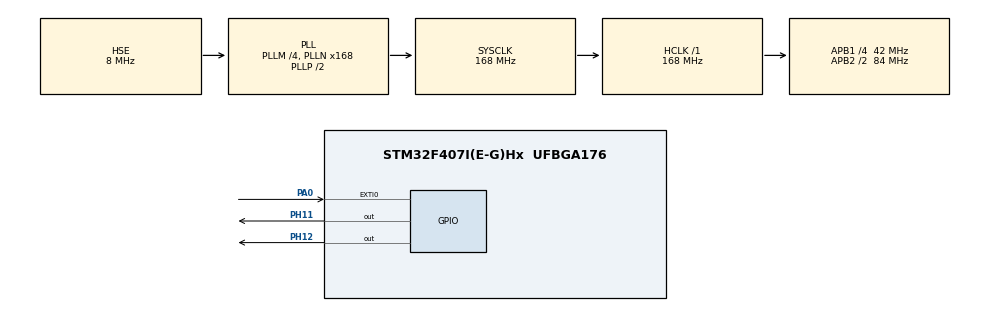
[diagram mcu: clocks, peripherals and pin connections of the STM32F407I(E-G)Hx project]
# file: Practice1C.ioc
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Mcu.Family=STM32F4
Mcu.Name=STM32F407I(E-G)Hx
Mcu.Package=UFBGA176
NVIC.EXTI0_IRQn=true\:0\:0\:false\:false\:true\:true\:true\:true
NVIC.PriorityGroup=NVIC_PRIORITYGROUP_4
NVIC.TIM3_IRQn=true\:0\:0\:false\:false\:true\:true\:true\:true
PA0-WKUP.GPIO_PuPd=GPIO_PULLDOWN
PA0-WKUP.Signal=GPXTI0
PA13.Mode=Serial_Wire
PA13.Signal=SYS_JTMS-SWDIO
PA14.Mode=Serial_Wire
PA14.Signal=SYS_JTCK-SWCLK
PH0-OSC_IN.Mode=HSE-External-Oscillator
PH0-OSC_IN.Signal=RCC_OSC_IN
PH1-OSC_OUT.Mode=HSE-External-Oscillator
PH1-OSC_OUT.Signal=RCC_OSC_OUT
PH11.PinState=GPIO_PIN_SET
PH11.Signal=GPIO_Output
PH12.PinState=GPIO_PIN_SET
PH12.Signal=GPIO_Output
ProjectManager.HeapSize=0x200
ProjectManager.StackSize=0x400
ProjectManager.TargetToolchain=CMake
RCC.48MHZClocksFreq_Value=84000000
RCC.AHBFreq_Value=168000000
RCC.APB1CLKDivider=RCC_HCLK_DIV4
RCC.APB1Freq_Value=42000000
RCC.APB1TimFreq_Value=84000000
RCC.APB2CLKDivider=RCC_HCLK_DIV2
RCC.APB2Freq_Value=84000000
RCC.APB2TimFreq_Value=168000000
RCC.CortexFreq_Value=168000000
RCC.HCLKFreq_Value=168000000
RCC.HSE_VALUE=8000000
RCC.HSI_VALUE=16000000
RCC.LSE_VALUE=32768
RCC.PLLM=4
RCC.PLLN=168
RCC.PLLSourceVirtual=RCC_PLLSOURCE_HSE
RCC.SYSCLKFreq_VALUE=168000000
RCC.SYSCLKSource=RCC_SYSCLKSOURCE_PLLCLK
RCC.VCOOutputFreq_Value=336000000
TIM3.Period=4999
TIM3.Prescaler=16799
VP_TIM3_VS_ClockSourceINT.Mode=Internal
board=custom

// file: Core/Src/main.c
/* USER CODE BEGIN Header */
/**
  ******************************************************************************
  * @file           : main.c
  * @brief          : Main program body
  ******************************************************************************
  * @attention
  *
  * Copyright (c) 2026 STMicroelectronics.
  * All rights reserved.
  *
  * This software is licensed under terms that can be found in the LICENSE file
  * in the root directory of this software component.
  * If no LICENSE file comes with this software, it is provided AS-IS.
  *
  ******************************************************************************
  */
/* USER CODE END Header */
#include "main.h"

/* USER CODE BEGIN PD */
volatile uint8_t tim3_event = 0;
/* USER CODE END PD */

TIM_HandleTypeDef htim3;

void SystemClock_Config(void);
static void MX_GPIO_Init(void);
static void MX_TIM3_Init(void);

int main(void)
{

  /* MCU Configuration--------------------------------------------------------*/

  /* Reset of all peripherals, Initializes the Flash interface and the Systick. */
  HAL_Init();

  /* Configure the system clock */
  SystemClock_Config();

  /* Initialize all configured peripherals */
  MX_GPIO_Init();
  MX_TIM3_Init();
  /* USER CODE BEGIN 2 */
   HAL_TIM_Base_Start_IT(&htim3);

  /* USER CODE END 2 */

  /* Infinite loop */
  /* USER CODE BEGIN WHILE */
  while (1)
  {

    HAL_GPIO_WritePin(GPIOH, GPIO_PIN_12, GPIO_PIN_RESET);
    HAL_GPIO_WritePin(GPIOH, GPIO_PIN_11, GPIO_PIN_SET);
    //HAL_GPIO_WritePin(GPIOH, GPIO_PIN_11, GPIO_PIN_SET);
    HAL_Delay(100);
     if (tim3_event == 1)
    {
        tim3_event = 0;  // 清除标志位

        // 在这里随便用 HAL_Delay，绝对安全！
        HAL_GPIO_TogglePin(GPIOH, GPIO_PIN_11); // 开灯
        HAL_GPIO_TogglePin(GPIOH, GPIO_PIN_12); // 关灯
        HAL_Delay(1000);                       // 延时 1 秒
    }
    /* USER CODE END WHILE */

  }
}

void SystemClock_Config(void)
{
  RCC_OscInitTypeDef RCC_OscInitStruct = {0};
  RCC_ClkInitTypeDef RCC_ClkInitStruct = {0};

  /** Configure the main internal regulator output voltage
  */
  __HAL_RCC_PWR_CLK_ENABLE();
  __HAL_PWR_VOLTAGESCALING_CONFIG(PWR_REGULATOR_VOLTAGE_SCALE1);

  /** Initializes the RCC Oscillators according to the specified parameters
  * in the RCC_OscInitTypeDef structure.
  */
  RCC_OscInitStruct.OscillatorType = RCC_OSCILLATORTYPE_HSE;
  RCC_OscInitStruct.HSEState = RCC_HSE_ON;
  RCC_OscInitStruct.PLL.PLLState = RCC_PLL_ON;
  RCC_OscInitStruct.PLL.PLLSource = RCC_PLLSOURCE_HSE;
  RCC_OscInitStruct.PLL.PLLM = 4;
  RCC_OscInitStruct.PLL.PLLN = 168;
  RCC_OscInitStruct.PLL.PLLP = RCC_PLLP_DIV2;
  RCC_OscInitStruct.PLL.PLLQ = 4;
  if (HAL_RCC_OscConfig(&RCC_OscInitStruct) != HAL_OK)
  {
    Error_Handler();
  }

  /** Initializes the CPU, AHB and APB buses clocks
  */
  RCC_ClkInitStruct.ClockType = RCC_CLOCKTYPE_HCLK|RCC_CLOCKTYPE_SYSCLK
                              |RCC_CLOCKTYPE_PCLK1|RCC_CLOCKTYPE_PCLK2;
  RCC_ClkInitStruct.SYSCLKSource = RCC_SYSCLKSOURCE_PLLCLK;
  RCC_ClkInitStruct.AHBCLKDivider = RCC_SYSCLK_DIV1;
  RCC_ClkInitStruct.APB1CLKDivider = RCC_HCLK_DIV4;
  RCC_ClkInitStruct.APB2CLKDivider = RCC_HCLK_DIV2;

  if (HAL_RCC_ClockConfig(&RCC_ClkInitStruct, FLASH_LATENCY_5) != HAL_OK)
  {
    Error_Handler();
  }
}

static void MX_TIM3_Init(void)
{

  TIM_ClockConfigTypeDef sClockSourceConfig = {0};
  TIM_MasterConfigTypeDef sMasterConfig = {0};

  htim3.Instance = TIM3;
  htim3.Init.Prescaler = 16799;
  htim3.Init.CounterMode = TIM_COUNTERMODE_UP;
  htim3.Init.Period = 4999;
  htim3.Init.ClockDivision = TIM_CLOCKDIVISION_DIV1;
  htim3.Init.AutoReloadPreload = TIM_AUTORELOAD_PRELOAD_DISABLE;
  if (HAL_TIM_Base_Init(&htim3) != HAL_OK)
  {
    Error_Handler();
  }
  sClockSourceConfig.ClockSource = TIM_CLOCKSOURCE_INTERNAL;
  if (HAL_TIM_ConfigClockSource(&htim3, &sClockSourceConfig) != HAL_OK)
  {
    Error_Handler();
  }
  sMasterConfig.MasterOutputTrigger = TIM_TRGO_RESET;
  sMasterConfig.MasterSlaveMode = TIM_MASTERSLAVEMODE_DISABLE;
  if (HAL_TIMEx_MasterConfigSynchronization(&htim3, &sMasterConfig) != HAL_OK)
  {
    Error_Handler();
  }

}

static void MX_GPIO_Init(void)
{
  GPIO_InitTypeDef GPIO_InitStruct = {0};

  /* GPIO Ports Clock Enable */
  __HAL_RCC_GPIOA_CLK_ENABLE();
  __HAL_RCC_GPIOH_CLK_ENABLE();

  /*Configure GPIO pin Output Level */
  HAL_GPIO_WritePin(GPIOH, GPIO_PIN_12|GPIO_PIN_11, GPIO_PIN_SET);

  /*Configure GPIO pins : PH12 PH11 */
  GPIO_InitStruct.Pin = GPIO_PIN_12|GPIO_PIN_11;
  GPIO_InitStruct.Mode = GPIO_MODE_OUTPUT_PP;
  GPIO_InitStruct.Pull = GPIO_NOPULL;
  GPIO_InitStruct.Speed = GPIO_SPEED_FREQ_LOW;
  HAL_GPIO_Init(GPIOH, &GPIO_InitStruct);

  /*Configure GPIO pin : PA0 */
  GPIO_InitStruct.Pin = GPIO_PIN_0;
  GPIO_InitStruct.Mode = GPIO_MODE_IT_RISING;
  GPIO_InitStruct.Pull = GPIO_PULLDOWN;
  HAL_GPIO_Init(GPIOA, &GPIO_InitStruct);

  /* EXTI interrupt init*/
  HAL_NVIC_SetPriority(EXTI0_IRQn, 0, 0);
  HAL_NVIC_EnableIRQ(EXTI0_IRQn);

}

/* USER CODE BEGIN 4 */
void HAL_TIM_PeriodElapsedCallback(TIM_HandleTypeDef *htim)
{
   tim3_event = 1;
    //TODO
}
/* USER CODE END 4 */

void Error_Handler(void)
{
  /* USER CODE BEGIN Error_Handler_Debug */
  /* User can add his own implementation to report the HAL error return state */
  __disable_irq();
  while (1)
  {
      HAL_GPIO_WritePin(GPIOH, GPIO_PIN_10, GPIO_PIN_SET);
  }
  /* USER CODE END Error_Handler_Debug */
}
